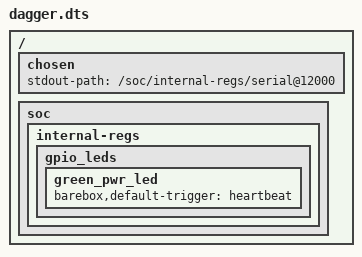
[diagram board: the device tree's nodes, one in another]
/*
 * Barebox specific DT overlay for Globalscale Mirabox
 *   Sebastian Hesselbarth <sebastian.hesselbarth@gmail.com>
 */

#include "arm/msys.dts"

/ {
	chosen {
		stdout-path = "/soc/internal-regs/serial@12000";
	};

	soc {
		internal-regs {
			gpio_leds {
				green_pwr_led {
					barebox,default-trigger = "heartbeat";
				};
			};
		};
	};
};
